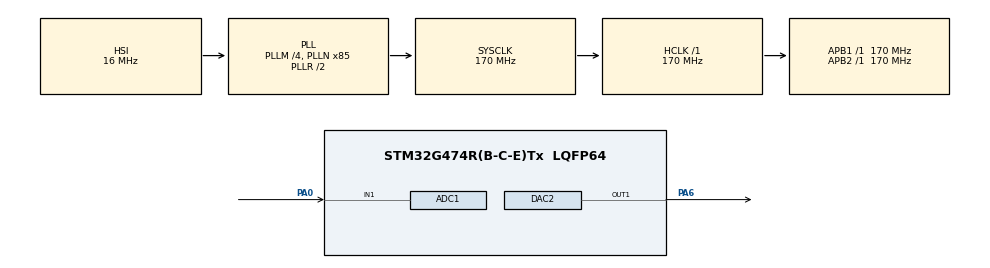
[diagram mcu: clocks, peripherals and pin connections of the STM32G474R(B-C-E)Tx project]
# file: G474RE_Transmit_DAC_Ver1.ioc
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ADC1.Channel-0\#ChannelRegularConversion=ADC_CHANNEL_1
ADC1.ContinuousConvMode=ENABLE
ADC1.DMAContinuousRequests=ENABLE
ADC1.NbrOfConversionFlag=1
ADC1.OffsetNumber-0\#ChannelRegularConversion=ADC_OFFSET_NONE
ADC1.Rank-0\#ChannelRegularConversion=1
ADC1.SamplingTime-0\#ChannelRegularConversion=ADC_SAMPLETIME_47CYCLES_5
ADC1.master=1
DAC2.DAC_Trigger_OUT1-DAC_OUT1=DAC_TRIGGER_T2_TRGO
Dma.ADC1.1.Direction=DMA_PERIPH_TO_MEMORY
Dma.ADC1.1.EventEnable=DISABLE
Dma.ADC1.1.Instance=DMA1_Channel2
Dma.ADC1.1.MemDataAlignment=DMA_MDATAALIGN_HALFWORD
Dma.ADC1.1.MemInc=DMA_MINC_ENABLE
Dma.ADC1.1.Mode=DMA_CIRCULAR
Dma.ADC1.1.PeriphDataAlignment=DMA_PDATAALIGN_HALFWORD
Dma.ADC1.1.PeriphInc=DMA_PINC_DISABLE
Dma.ADC1.1.Polarity=HAL_DMAMUX_REQ_GEN_RISING
Dma.ADC1.1.Priority=DMA_PRIORITY_MEDIUM
Dma.ADC1.1.RequestNumber=1
Dma.ADC1.1.SignalID=NONE
Dma.ADC1.1.SyncEnable=DISABLE
Dma.ADC1.1.SyncPolarity=HAL_DMAMUX_SYNC_NO_EVENT
Dma.ADC1.1.SyncRequestNumber=1
Dma.ADC1.1.SyncSignalID=NONE
Dma.DAC2_CH1.0.Direction=DMA_MEMORY_TO_PERIPH
Dma.DAC2_CH1.0.EventEnable=DISABLE
Dma.DAC2_CH1.0.Instance=DMA1_Channel1
Dma.DAC2_CH1.0.MemDataAlignment=DMA_MDATAALIGN_HALFWORD
Dma.DAC2_CH1.0.MemInc=DMA_MINC_ENABLE
Dma.DAC2_CH1.0.Mode=DMA_CIRCULAR
Dma.DAC2_CH1.0.PeriphDataAlignment=DMA_PDATAALIGN_WORD
Dma.DAC2_CH1.0.PeriphInc=DMA_PINC_DISABLE
Dma.DAC2_CH1.0.Polarity=HAL_DMAMUX_REQ_GEN_RISING
Dma.DAC2_CH1.0.Priority=DMA_PRIORITY_MEDIUM
Dma.DAC2_CH1.0.RequestNumber=1
Dma.DAC2_CH1.0.SignalID=NONE
Dma.DAC2_CH1.0.SyncEnable=DISABLE
Dma.DAC2_CH1.0.SyncPolarity=HAL_DMAMUX_SYNC_NO_EVENT
Dma.DAC2_CH1.0.SyncRequestNumber=1
Dma.DAC2_CH1.0.SyncSignalID=NONE
Dma.Request0=DAC2_CH1
Dma.Request1=ADC1
Mcu.Family=STM32G4
Mcu.Name=STM32G474R(B-C-E)Tx
Mcu.Package=LQFP64
NVIC.DMA1_Channel1_IRQn=true\:0\:0\:false\:false\:true\:false\:true\:true
NVIC.DMA1_Channel2_IRQn=true\:0\:0\:false\:false\:true\:false\:true\:true
NVIC.PriorityGroup=NVIC_PRIORITYGROUP_4
PA0.Mode=IN1-Single-Ended
PA0.Signal=ADC1_IN1
PA13.Mode=Serial_Wire
PA13.Signal=SYS_JTMS-SWDIO
PA14.Mode=Serial_Wire
PA14.Signal=SYS_JTCK-SWCLK
PA6.Signal=COMP_DAC21_group
PC14-OSC32_IN.Mode=LSE-External-Oscillator
PC14-OSC32_IN.Signal=RCC_OSC32_IN
PC15-OSC32_OUT.Mode=LSE-External-Oscillator
PC15-OSC32_OUT.Signal=RCC_OSC32_OUT
PF0-OSC_IN.Mode=HSE-External-Oscillator
PF0-OSC_IN.Signal=RCC_OSC_IN
PF1-OSC_OUT.Mode=HSE-External-Oscillator
PF1-OSC_OUT.Signal=RCC_OSC_OUT
ProjectManager.HeapSize=0x200
ProjectManager.StackSize=0x400
ProjectManager.TargetToolchain=STM32CubeIDE
RCC.ADC12Freq_Value=170000000
RCC.ADC345Freq_Value=170000000
RCC.AHBFreq_Value=170000000
RCC.APB1Freq_Value=170000000
RCC.APB1TimFreq_Value=170000000
RCC.APB2Freq_Value=170000000
RCC.APB2TimFreq_Value=170000000
RCC.CortexFreq_Value=170000000
RCC.EXTERNAL_CLOCK_VALUE=12288000
RCC.HCLKFreq_Value=170000000
RCC.HSE_VALUE=8000000
RCC.HSI48_VALUE=48000000
RCC.HSI_VALUE=16000000
RCC.PLLM=RCC_PLLM_DIV4
RCC.PLLN=85
RCC.SYSCLKFreq_VALUE=170000000
RCC.SYSCLKSource=RCC_SYSCLKSOURCE_PLLCLK
RCC.USBFreq_Value=170000000
RCC.VCOOutputFreq_Value=340000000
SH.COMP_DAC21_group.0=DAC2_OUT1,DAC_OUT1
TIM2.PeriodNoDither=24
TIM2.Prescaler=169
TIM2.TIM_MasterOutputTrigger=TIM_TRGO_UPDATE
VP_SYS_VS_DBSignals.Mode=DisableDeadBatterySignals
VP_TIM2_VS_ClockSourceINT.Mode=Internal
board=custom

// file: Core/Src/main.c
/* USER CODE BEGIN Header */
/**
 ******************************************************************************
 * @file           : main.c
 * @brief          : Main program body
 ******************************************************************************
 * @attention
 *
 * Copyright (c) 2025 STMicroelectronics.
 * All rights reserved.
 *
 * This software is licensed under terms that can be found in the LICENSE file
 * in the root directory of this software component.
 * If no LICENSE file comes with this software, it is provided AS-IS.
 *
 ******************************************************************************
 */
/* USER CODE END Header */
#include "main.h"

/* USER CODE BEGIN Includes */
#include<math.h>
#include <string.h>
#ifndef M_PI
#define M_PI 3.14159265358979323846
#endif
/* USER CODE END Includes */

/* USER CODE BEGIN PTD */
#define DAC_MAX         4095
#define SAMPLE_RATE     40000      // Hz
#define BIT_RATE        800        // bits per second
#define SAMPLES_PER_BIT (SAMPLE_RATE / BIT_RATE)
#define BUFFER_LEN      200

#define TONE_MARK       1500       // Hz
#define TONE_SPACE      2500       // Hz
/* USER CODE END PTD */

/* USER CODE BEGIN PD */
char message[] = "HELLO";
uint8_t msg_index = 0;
uint8_t bit_index = 0;
uint8_t current_bit = 0;

/* DAC buffer ----------------------------------------------------------------*/
uint16_t dac_buffer[BUFFER_LEN];
double phase = 0.0;
double phase_inc = 0.0;
uint32_t sample_count = 0;
void FillBuffer(int offset, int length);
/* USER CODE END PD */

ADC_HandleTypeDef hadc1;
DMA_HandleTypeDef hdma_adc1;

DAC_HandleTypeDef hdac2;
DMA_HandleTypeDef hdma_dac2_ch1;

TIM_HandleTypeDef htim2;

void SystemClock_Config(void);
static void MX_GPIO_Init(void);
static void MX_DMA_Init(void);
static void MX_DAC2_Init(void);
static void MX_TIM2_Init(void);
static void MX_ADC1_Init(void);

/* USER CODE BEGIN 0 */
void FillBuffer(int offset, int length) {
	for (int i = 0; i < length; i++) {
		dac_buffer[offset + i] =
				(uint16_t) ((sin(phase) + 1.0) * (DAC_MAX / 2));

		phase += phase_inc;
		if (phase >= 2.0 * M_PI)
			phase -= 2.0 * M_PI;

		sample_count++;
		if (sample_count >= SAMPLES_PER_BIT) {
			sample_count = 0;

			// Get next bit
			current_bit = (message[msg_index] >> bit_index) & 1;
			bit_index++;
			if (bit_index >= 8) {
				bit_index = 0;
				msg_index++;
				if (msg_index >= strlen(message))
					msg_index = 0;
			}

			// Set tone frequency
			if (current_bit)
				phase_inc = 2.0 * M_PI * TONE_MARK / SAMPLE_RATE;
			else
				phase_inc = 2.0 * M_PI * TONE_SPACE / SAMPLE_RATE;
		}
	}
}

void HAL_DAC_ConvHalfCpltCallbackCh1(DAC_HandleTypeDef *hdac) {
	FillBuffer(0, BUFFER_LEN / 2);
}

void HAL_DAC_ConvCpltCallbackCh1(DAC_HandleTypeDef *hdac) {
	FillBuffer(BUFFER_LEN / 2, BUFFER_LEN / 2);
}

/* USER CODE END 0 */

int main(void)
{

  /* MCU Configuration--------------------------------------------------------*/

  /* Reset of all peripherals, Initializes the Flash interface and the Systick. */
  HAL_Init();

  /* Configure the system clock */
  SystemClock_Config();

  /* Initialize all configured peripherals */
  MX_GPIO_Init();
  MX_DMA_Init();
  MX_DAC2_Init();
  MX_TIM2_Init();
  MX_ADC1_Init();
  /* USER CODE BEGIN 2 */
	current_bit = (message[msg_index] >> bit_index) & 1;
	if (current_bit)
		phase_inc = 2.0 * M_PI * TONE_MARK / SAMPLE_RATE;
	else
		phase_inc = 2.0 * M_PI * TONE_SPACE / SAMPLE_RATE;

	HAL_TIM_Base_Start(&htim2);
	HAL_DAC_Start_DMA(&hdac2, DAC_CHANNEL_1, (uint32_t*) dac_buffer, BUFFER_LEN,
			DAC_ALIGN_12B_R);

  /* USER CODE END 2 */

  /* Infinite loop */
	while (1) {

	}
}

void SystemClock_Config(void)
{
  RCC_OscInitTypeDef RCC_OscInitStruct = {0};
  RCC_ClkInitTypeDef RCC_ClkInitStruct = {0};

  /** Configure the main internal regulator output voltage
  */
  HAL_PWREx_ControlVoltageScaling(PWR_REGULATOR_VOLTAGE_SCALE1_BOOST);

  /** Initializes the RCC Oscillators according to the specified parameters
  * in the RCC_OscInitTypeDef structure.
  */
  RCC_OscInitStruct.OscillatorType = RCC_OSCILLATORTYPE_HSI;
  RCC_OscInitStruct.HSIState = RCC_HSI_ON;
  RCC_OscInitStruct.HSICalibrationValue = RCC_HSICALIBRATION_DEFAULT;
  RCC_OscInitStruct.PLL.PLLState = RCC_PLL_ON;
  RCC_OscInitStruct.PLL.PLLSource = RCC_PLLSOURCE_HSI;
  RCC_OscInitStruct.PLL.PLLM = RCC_PLLM_DIV4;
  RCC_OscInitStruct.PLL.PLLN = 85;
  RCC_OscInitStruct.PLL.PLLP = RCC_PLLP_DIV2;
  RCC_OscInitStruct.PLL.PLLQ = RCC_PLLQ_DIV2;
  RCC_OscInitStruct.PLL.PLLR = RCC_PLLR_DIV2;
  if (HAL_RCC_OscConfig(&RCC_OscInitStruct) != HAL_OK)
  {
    Error_Handler();
  }

  /** Initializes the CPU, AHB and APB buses clocks
  */
  RCC_ClkInitStruct.ClockType = RCC_CLOCKTYPE_HCLK|RCC_CLOCKTYPE_SYSCLK
                              |RCC_CLOCKTYPE_PCLK1|RCC_CLOCKTYPE_PCLK2;
  RCC_ClkInitStruct.SYSCLKSource = RCC_SYSCLKSOURCE_PLLCLK;
  RCC_ClkInitStruct.AHBCLKDivider = RCC_SYSCLK_DIV1;
  RCC_ClkInitStruct.APB1CLKDivider = RCC_HCLK_DIV1;
  RCC_ClkInitStruct.APB2CLKDivider = RCC_HCLK_DIV1;

  if (HAL_RCC_ClockConfig(&RCC_ClkInitStruct, FLASH_LATENCY_4) != HAL_OK)
  {
    Error_Handler();
  }
}

static void MX_ADC1_Init(void)
{

  ADC_MultiModeTypeDef multimode = {0};
  ADC_ChannelConfTypeDef sConfig = {0};

  /** Common config
  */
  hadc1.Instance = ADC1;
  hadc1.Init.ClockPrescaler = ADC_CLOCK_SYNC_PCLK_DIV4;
  hadc1.Init.Resolution = ADC_RESOLUTION_12B;
  hadc1.Init.DataAlign = ADC_DATAALIGN_RIGHT;
  hadc1.Init.GainCompensation = 0;
  hadc1.Init.ScanConvMode = ADC_SCAN_DISABLE;
  hadc1.Init.EOCSelection = ADC_EOC_SINGLE_CONV;
  hadc1.Init.LowPowerAutoWait = DISABLE;
  hadc1.Init.ContinuousConvMode = ENABLE;
  hadc1.Init.NbrOfConversion = 1;
  hadc1.Init.DiscontinuousConvMode = DISABLE;
  hadc1.Init.ExternalTrigConv = ADC_SOFTWARE_START;
  hadc1.Init.ExternalTrigConvEdge = ADC_EXTERNALTRIGCONVEDGE_NONE;
  hadc1.Init.DMAContinuousRequests = ENABLE;
  hadc1.Init.Overrun = ADC_OVR_DATA_PRESERVED;
  hadc1.Init.OversamplingMode = DISABLE;
  if (HAL_ADC_Init(&hadc1) != HAL_OK)
  {
    Error_Handler();
  }

  /** Configure the ADC multi-mode
  */
  multimode.Mode = ADC_MODE_INDEPENDENT;
  if (HAL_ADCEx_MultiModeConfigChannel(&hadc1, &multimode) != HAL_OK)
  {
    Error_Handler();
  }

  /** Configure Regular Channel
  */
  sConfig.Channel = ADC_CHANNEL_1;
  sConfig.Rank = ADC_REGULAR_RANK_1;
  sConfig.SamplingTime = ADC_SAMPLETIME_47CYCLES_5;
  sConfig.SingleDiff = ADC_SINGLE_ENDED;
  sConfig.OffsetNumber = ADC_OFFSET_NONE;
  sConfig.Offset = 0;
  if (HAL_ADC_ConfigChannel(&hadc1, &sConfig) != HAL_OK)
  {
    Error_Handler();
  }

}

static void MX_DAC2_Init(void)
{

  DAC_ChannelConfTypeDef sConfig = {0};

  /** DAC Initialization
  */
  hdac2.Instance = DAC2;
  if (HAL_DAC_Init(&hdac2) != HAL_OK)
  {
    Error_Handler();
  }

  /** DAC channel OUT1 config
  */
  sConfig.DAC_HighFrequency = DAC_HIGH_FREQUENCY_INTERFACE_MODE_AUTOMATIC;
  sConfig.DAC_DMADoubleDataMode = DISABLE;
  sConfig.DAC_SignedFormat = DISABLE;
  sConfig.DAC_SampleAndHold = DAC_SAMPLEANDHOLD_DISABLE;
  sConfig.DAC_Trigger = DAC_TRIGGER_T2_TRGO;
  sConfig.DAC_Trigger2 = DAC_TRIGGER_NONE;
  sConfig.DAC_OutputBuffer = DAC_OUTPUTBUFFER_ENABLE;
  sConfig.DAC_ConnectOnChipPeripheral = DAC_CHIPCONNECT_EXTERNAL;
  sConfig.DAC_UserTrimming = DAC_TRIMMING_FACTORY;
  if (HAL_DAC_ConfigChannel(&hdac2, &sConfig, DAC_CHANNEL_1) != HAL_OK)
  {
    Error_Handler();
  }

}

static void MX_TIM2_Init(void)
{

  TIM_ClockConfigTypeDef sClockSourceConfig = {0};
  TIM_MasterConfigTypeDef sMasterConfig = {0};

  htim2.Instance = TIM2;
  htim2.Init.Prescaler = 169;
  htim2.Init.CounterMode = TIM_COUNTERMODE_UP;
  htim2.Init.Period = 24;
  htim2.Init.ClockDivision = TIM_CLOCKDIVISION_DIV1;
  htim2.Init.AutoReloadPreload = TIM_AUTORELOAD_PRELOAD_DISABLE;
  if (HAL_TIM_Base_Init(&htim2) != HAL_OK)
  {
    Error_Handler();
  }
  sClockSourceConfig.ClockSource = TIM_CLOCKSOURCE_INTERNAL;
  if (HAL_TIM_ConfigClockSource(&htim2, &sClockSourceConfig) != HAL_OK)
  {
    Error_Handler();
  }
  sMasterConfig.MasterOutputTrigger = TIM_TRGO_UPDATE;
  sMasterConfig.MasterSlaveMode = TIM_MASTERSLAVEMODE_DISABLE;
  if (HAL_TIMEx_MasterConfigSynchronization(&htim2, &sMasterConfig) != HAL_OK)
  {
    Error_Handler();
  }

}

static void MX_DMA_Init(void)
{

  /* DMA controller clock enable */
  __HAL_RCC_DMAMUX1_CLK_ENABLE();
  __HAL_RCC_DMA1_CLK_ENABLE();

  /* DMA interrupt init */
  /* DMA1_Channel1_IRQn interrupt configuration */
  HAL_NVIC_SetPriority(DMA1_Channel1_IRQn, 0, 0);
  HAL_NVIC_EnableIRQ(DMA1_Channel1_IRQn);
  /* DMA1_Channel2_IRQn interrupt configuration */
  HAL_NVIC_SetPriority(DMA1_Channel2_IRQn, 0, 0);
  HAL_NVIC_EnableIRQ(DMA1_Channel2_IRQn);

}

static void MX_GPIO_Init(void)
{

  /* GPIO Ports Clock Enable */
  __HAL_RCC_GPIOC_CLK_ENABLE();
  __HAL_RCC_GPIOF_CLK_ENABLE();
  __HAL_RCC_GPIOA_CLK_ENABLE();

}

void Error_Handler(void)
{
	__disable_irq();
	while (1) {
	}
}
